# UCS__Unified_System_Clock_6 register map
Vendor: Texas Instruments
Peripheral module from a debugger description file (folder msp430).
Registers are 16-bit, read-write, reset 0x0 unless marked. A register's access mark holds for its fields unless they carry their own. Offsets are as the file gives them; lines under a group give offsets from that group; [hi:lo] are bit positions; {n}, {i} and the like mark numbered series; 'fields as' and 'values as' point back to an identical list; <NAME> marks a mode.

## UCS_Unified_System_Clock
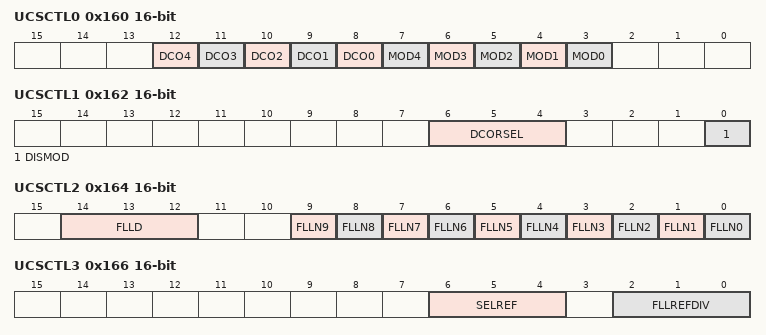
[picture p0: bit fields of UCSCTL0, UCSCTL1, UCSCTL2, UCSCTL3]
0x160 UCSCTL0 — UCS Control Register 0
  [n+8] DCO{n} (n=0..4) — DCO TAP Bit : {n}
  [n+3] MOD{n} (n=0..4) — Modulation Bit Counter Bit : {n}
0x162 UCSCTL1 — UCS Control Register 1
  [6:4] DCORSEL — DCO Freq. Range Select Bit : 0
  [0] DISMOD — Disable Modulation
0x164 UCSCTL2 — UCS Control Register 2
  [14:12] FLLD — Loop Divider Bit : 0
    0=Multiply Selected Loop Freq. 1; 1=Multiply Selected Loop Freq. 2; 2=Multiply Selected Loop Freq. 4; 3=Multiply Selected Loop Freq. 8; 4=Multiply Selected Loop Freq. 16; 5=Multiply Selected Loop Freq. 32; 6=Multiply Selected Loop Freq. 32; 7=Multiply Selected Loop Freq. 32
  [n] FLLN{n} (n=0..9) — FLL Multipier Bit : {n}
0x166 UCSCTL3 — UCS Control Register 3
  [6:4] SELREF — FLL Reference Clock Select Bit : 0
    {v}=FLL Reference Clock Select {v} (v=0..7)
  [2:0] FLLREFDIV — Reference Divider Bit : 0
    0=Reference Divider: f(LFCLK)/1; 1=Reference Divider: f(LFCLK)/2; 2=Reference Divider: f(LFCLK)/4; 3=Reference Divider: f(LFCLK)/8; 4=Reference Divider: f(LFCLK)/12; 5=Reference Divider: f(LFCLK)/16; 6=Reference Divider: f(LFCLK)/16; 7=Reference Divider: f(LFCLK)/16
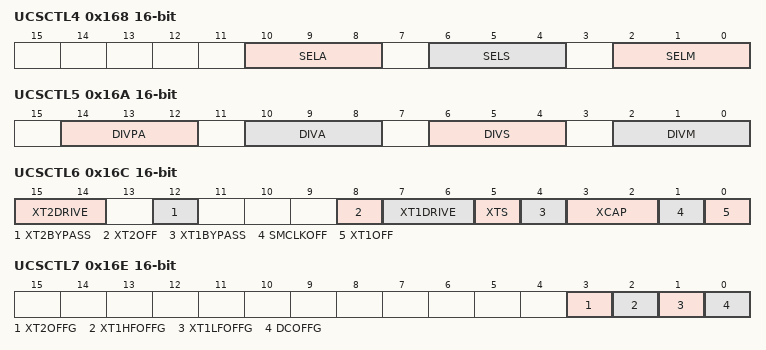
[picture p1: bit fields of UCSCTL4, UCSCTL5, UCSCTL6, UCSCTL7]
0x168 UCSCTL4 — UCS Control Register 4
  [10:8] SELA — ACLK Source Select Bit: 0
    {v}=ACLK Source Select {v} (v=0..7)
  [6:4] SELS — SMCLK Source Select Bit: 0
    {v}=SMCLK Source Select {v} (v=0..7)
  [2:0] SELM — MCLK Source Select Bit: 0
    {v}=MCLK Source Select {v} (v=0..7)
0x16A UCSCTL5 — UCS Control Register 5
  [14:12] DIVPA — ACLK from Pin Divider Bit: 0
    {v}=ACLK from Pin Source Divider {v} (v=0..7)
  [10:8] DIVA — ACLK Divider Bit: 0
    {v}=ACLK Source Divider {v} (v=0..7)
  [6:4] DIVS — SMCLK Divider Bit: 0
    {v}=SMCLK Source Divider {v} (v=0..7)
  [2:0] DIVM — MCLK Divider Bit: 0
    {v}=MCLK Source Divider {v} (v=0..7)
0x16C UCSCTL6 — UCS Control Register 6
  [15:14] XT2DRIVE — XT2 Drive Level mode Bit 0
    {v}=XT2 Drive Level mode: {v} (v=0..3)
  [12] XT2BYPASS — XT2 bypass mode : 0: internal 1:sourced from external pin
  [8] XT2OFF — High Frequency Oscillator 2 (XT2) disable
  [7:6] XT1DRIVE — XT1 Drive Level mode Bit 0
    {v}=XT1 Drive Level mode: {v} (v=0..3)
  [5] XTS — 1: Selects high-freq. oscillator
  [4] XT1BYPASS — XT1 bypass mode : 0: internal 1:sourced from external pin
  [3:2] XCAP — XIN/XOUT Cap Bit: 0
    {v}=XIN/XOUT Cap {v} (v=0..3)
  [1] SMCLKOFF
  [0] XT1OFF — High Frequency Oscillator 1 (XT1) disable
0x16E UCSCTL7 — UCS Control Register 7
  [3] XT2OFFG — High Frequency Oscillator 2 Fault Flag
  [2] XT1HFOFFG — XT1 High Frequency Oscillator 1 Fault Flag
  [1] XT1LFOFFG — XT1 Low Frequency Oscillator Fault Flag
  [0] DCOFFG — DCO Fault Flag
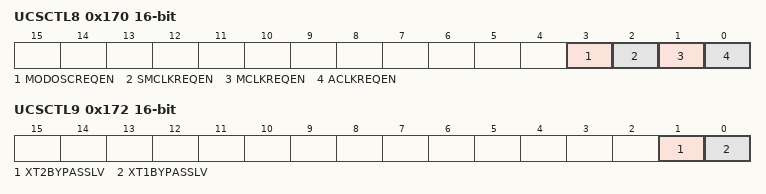
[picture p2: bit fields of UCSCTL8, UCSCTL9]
0x170 UCSCTL8 — UCS Control Register 8
  [3] MODOSCREQEN — MODOSC Clock Request Enable
  [2] SMCLKREQEN — SMCLK Clock Request Enable
  [1] MCLKREQEN — MCLK Clock Request Enable
  [0] ACLKREQEN — ACLK Clock Request Enable
0x172 UCSCTL9 — UCS Control Register 9
  [1] XT2BYPASSLV — Selects XT2 bypass input swing level
  [0] XT1BYPASSLV — Selects XT1 bypass input swing level
